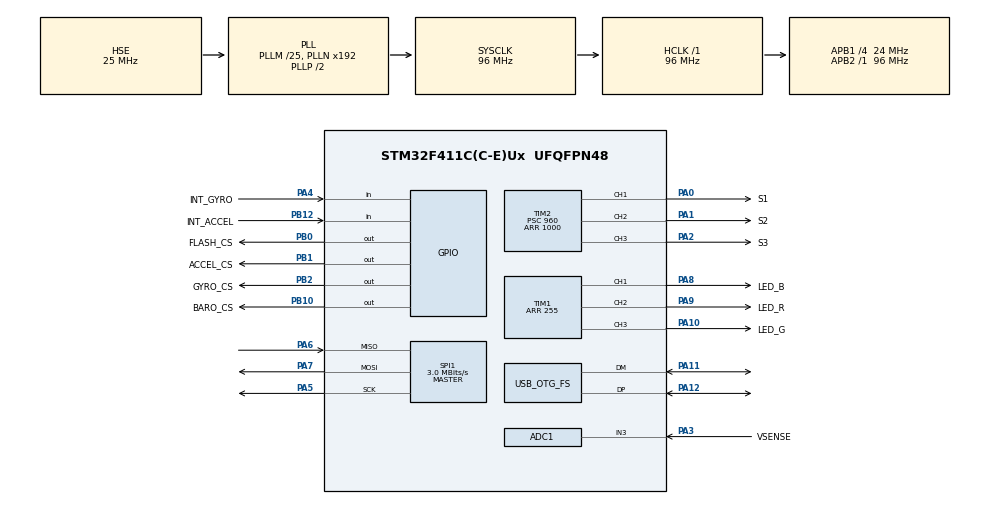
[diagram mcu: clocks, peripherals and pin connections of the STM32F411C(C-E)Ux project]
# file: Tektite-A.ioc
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ADC1.Channel-0\#ChannelRegularConversion=ADC_CHANNEL_3
ADC1.NbrOfConversionFlag=1
ADC1.Rank-0\#ChannelRegularConversion=1
ADC1.SamplingTime-0\#ChannelRegularConversion=ADC_SAMPLETIME_3CYCLES
ADC1.master=1
Mcu.Family=STM32F4
Mcu.Name=STM32F411C(C-E)Ux
Mcu.Package=UFQFPN48
NVIC.OTG_FS_IRQn=true\:0\:0\:false\:false\:true\:false\:true\:true
NVIC.PriorityGroup=NVIC_PRIORITYGROUP_4
NimaLTD.I-CUBE-SPIF.2.3.1.DriverJjSPIF=true
NimaLTD.I-CUBE-SPIF.2.3.1.SPIF_DEBUG=SPIF_DEBUG_DISABLE
PA0-WKUP.GPIO_Label=S1
PA0-WKUP.GPIO_PuPd=GPIO_PULLDOWN
PA0-WKUP.Signal=S_TIM2_CH1_ETR
PA1.GPIO_Label=S2
PA1.GPIO_PuPd=GPIO_PULLDOWN
PA1.Signal=S_TIM2_CH2
PA10.GPIO_Label=LED_G
PA10.Signal=S_TIM1_CH3
PA11.Mode=Device_Only
PA11.Signal=USB_OTG_FS_DM
PA12.Mode=Device_Only
PA12.Signal=USB_OTG_FS_DP
PA13.Mode=Serial_Wire
PA13.Signal=SYS_JTMS-SWDIO
PA14.Mode=Serial_Wire
PA14.Signal=SYS_JTCK-SWCLK
PA2.GPIO_Label=S3
PA2.GPIO_PuPd=GPIO_PULLDOWN
PA2.Signal=S_TIM2_CH3
PA3.GPIO_Label=VSENSE
PA3.Signal=ADCx_IN3
PA4.GPIO_Label=INT_GYRO
PA4.Signal=GPIO_Input
PA5.Mode=Full_Duplex_Master
PA5.Signal=SPI1_SCK
PA6.Mode=Full_Duplex_Master
PA6.Signal=SPI1_MISO
PA7.Mode=Full_Duplex_Master
PA7.Signal=SPI1_MOSI
PA8.GPIO_Label=LED_B
PA8.Signal=S_TIM1_CH1
PA9.GPIO_Label=LED_R
PA9.Signal=S_TIM1_CH2
PB0.GPIO_Label=FLASH_CS
PB0.GPIO_Speed=GPIO_SPEED_FREQ_VERY_HIGH
PB0.PinState=GPIO_PIN_SET
PB0.Signal=GPIO_Output
PB1.GPIO_Label=ACCEL_CS
PB1.GPIO_Speed=GPIO_SPEED_FREQ_VERY_HIGH
PB1.PinState=GPIO_PIN_SET
PB1.Signal=GPIO_Output
PB10.GPIO_Label=BARO_CS
PB10.GPIO_Speed=GPIO_SPEED_FREQ_VERY_HIGH
PB10.PinState=GPIO_PIN_SET
PB10.Signal=GPIO_Output
PB12.GPIO_Label=INT_ACCEL
PB12.Signal=GPIO_Input
PB2.GPIO_Label=GYRO_CS
PB2.GPIO_Speed=GPIO_SPEED_FREQ_VERY_HIGH
PB2.PinState=GPIO_PIN_SET
PB2.Signal=GPIO_Output
PH0\ -\ OSC_IN.Mode=HSE-External-Oscillator
PH0\ -\ OSC_IN.Signal=RCC_OSC_IN
PH1\ -\ OSC_OUT.Mode=HSE-External-Oscillator
PH1\ -\ OSC_OUT.Signal=RCC_OSC_OUT
ProjectManager.HeapSize=0x200
ProjectManager.StackSize=0x400
ProjectManager.TargetToolchain=STM32CubeIDE
RCC.48MHZClocksFreq_Value=48000000
RCC.AHBFreq_Value=96000000
RCC.APB1CLKDivider=RCC_HCLK_DIV4
RCC.APB1Freq_Value=24000000
RCC.APB1TimFreq_Value=48000000
RCC.APB2Freq_Value=96000000
RCC.APB2TimFreq_Value=96000000
RCC.CortexFreq_Value=96000000
RCC.HCLKFreq_Value=96000000
RCC.HSE_VALUE=25000000
RCC.HSI_VALUE=16000000
RCC.LSE_VALUE=32768
RCC.PLLM=25
RCC.SYSCLKFreq_VALUE=96000000
RCC.SYSCLKSource=RCC_SYSCLKSOURCE_PLLCLK
RCC.VCOOutputFreq_Value=192000000
SH.ADCx_IN3.0=ADC1_IN3,IN3
SH.S_TIM1_CH1.0=TIM1_CH1,PWM Generation1 CH1
SH.S_TIM1_CH2.0=TIM1_CH2,PWM Generation2 CH2
SH.S_TIM1_CH3.0=TIM1_CH3,PWM Generation3 CH3
SH.S_TIM2_CH1_ETR.0=TIM2_CH1,PWM Generation1 CH1
SH.S_TIM2_CH2.0=TIM2_CH2,PWM Generation2 CH2
SH.S_TIM2_CH3.0=TIM2_CH3,PWM Generation3 CH3
SPI1.BaudRatePrescaler=SPI_BAUDRATEPRESCALER_32
SPI1.CalculateBaudRate=3.0 MBits/s
SPI1.DataSize=SPI_DATASIZE_8BIT
SPI1.Direction=SPI_DIRECTION_2LINES
SPI1.Mode=SPI_MODE_MASTER
SPI1.VirtualType=VM_MASTER
TIM1.AutoReloadPreload=TIM_AUTORELOAD_PRELOAD_ENABLE
TIM1.Channel-PWM\ Generation1\ CH1=TIM_CHANNEL_1
TIM1.Channel-PWM\ Generation2\ CH2=TIM_CHANNEL_2
TIM1.Channel-PWM\ Generation3\ CH3=TIM_CHANNEL_3
TIM1.Period=255
TIM2.Channel-PWM\ Generation1\ CH1=TIM_CHANNEL_1
TIM2.Channel-PWM\ Generation2\ CH2=TIM_CHANNEL_2
TIM2.Channel-PWM\ Generation3\ CH3=TIM_CHANNEL_3
TIM2.Period=1000
TIM2.Prescaler=960
USB_DEVICE.CLASS_NAME_FS=CDC
USB_DEVICE.VirtualMode=Cdc
USB_DEVICE.VirtualModeFS=Cdc_FS
USB_OTG_FS.VirtualMode=Device_Only
VP_NimaLTD.I-CUBE-SPIF_VS_DriverJjSPIF_1.0.0_2.3.1.Mode=DriverJjSPIF
VP_TIM1_VS_ClockSourceINT.Mode=Internal
VP_TIM2_VS_ClockSourceINT.Mode=Internal
VP_USB_DEVICE_VS_USB_DEVICE_CDC_FS.Mode=CDC_FS
board=custom

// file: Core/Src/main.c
/* USER CODE BEGIN Header */
/**
  ******************************************************************************
  * @file           : main.c
  * @brief          : Main program body
  ******************************************************************************
  * @attention
  *
  * Copyright (c) 2024 STMicroelectronics.
  * All rights reserved.
  *
  * This software is licensed under terms that can be found in the LICENSE file
  * in the root directory of this software component.
  * If no LICENSE file comes with this software, it is provided AS-IS.
  *
  ******************************************************************************
  */
/* USER CODE END Header */
#include "main.h"
#include "adc.h"
#include "spi.h"
#include "tim.h"
#include "usb_device.h"
#include "gpio.h"

/* USER CODE BEGIN Includes */
#include <string.h>
#include <math.h>
#include "sensor.h"
#include "states.h"
/* USER CODE END Includes */

void SystemClock_Config(void);
/* USER CODE BEGIN PFP */
extern uint8_t CDC_Transmit_FS(uint8_t* Buf, uint16_t Len);
/* USER CODE END PFP */

int main(void)
{

  /* MCU Configuration--------------------------------------------------------*/

  /* Reset of all peripherals, Initializes the Flash interface and the Systick. */
  HAL_Init();

  /* Configure the system clock */
  SystemClock_Config();

  /* Initialize all configured peripherals */
  MX_GPIO_Init();
  MX_SPI1_Init();
  MX_USB_DEVICE_Init();
  MX_TIM2_Init();
  MX_TIM1_Init();
  MX_ADC1_Init();
  /* USER CODE BEGIN 2 */
  SensorInit();
  //CalcStdev();

  // Filter testing code
  SensorRawUpdate();
  SensorFilterReset();

  //float sigmaTot = 0;

  /*float total = 0;
  float values[1000];
  for (int i = 0; i < 1000; i++) {
	  LEDWrite(i/6, i/6, i/6);
	  SensorRawUpdate();
	  total += state.altr;
	  values[i] = state.altr;
	  HAL_Delay(12);
  }
  for (int i = 0; i < 1000; i++) {
	  sigmaTot += powf(((total/1000.0f)-values[i]), 2.0f);
  }
  sigmaTot = sqrtf(sigmaTot/999.0f);*/

  /*int sc = 0;
  while (1) {
	  SensorRawUpdate();
	  SensorFilterUpdate();
	  sc++;
	  if (sc % 50 == 0) {
		 printf("alt:%f,vz:%f,az:%f,altr:%f,vD:%f,sigma:%f\n", state.alt, state.vz, state.az, state.altr, delayedVel, sigmaTot);
	  }
  }*/

  /* USER CODE END 2 */

  /* Infinite loop */
  while (1)
  {

    /* USER CODE BEGIN 3 */
	 SensorRawUpdate();
	 StateUpdate();
  }
  /* USER CODE END 3 */
}

void SystemClock_Config(void)
{
  RCC_OscInitTypeDef RCC_OscInitStruct = {0};
  RCC_ClkInitTypeDef RCC_ClkInitStruct = {0};

  /** Configure the main internal regulator output voltage
  */
  __HAL_RCC_PWR_CLK_ENABLE();
  __HAL_PWR_VOLTAGESCALING_CONFIG(PWR_REGULATOR_VOLTAGE_SCALE1);

  /** Initializes the RCC Oscillators according to the specified parameters
  * in the RCC_OscInitTypeDef structure.
  */
  RCC_OscInitStruct.OscillatorType = RCC_OSCILLATORTYPE_HSE;
  RCC_OscInitStruct.HSEState = RCC_HSE_ON;
  RCC_OscInitStruct.PLL.PLLState = RCC_PLL_ON;
  RCC_OscInitStruct.PLL.PLLSource = RCC_PLLSOURCE_HSE;
  RCC_OscInitStruct.PLL.PLLM = 25;
  RCC_OscInitStruct.PLL.PLLN = 192;
  RCC_OscInitStruct.PLL.PLLP = RCC_PLLP_DIV2;
  RCC_OscInitStruct.PLL.PLLQ = 4;
  if (HAL_RCC_OscConfig(&RCC_OscInitStruct) != HAL_OK)
  {
    Error_Handler();
  }

  /** Initializes the CPU, AHB and APB buses clocks
  */
  RCC_ClkInitStruct.ClockType = RCC_CLOCKTYPE_HCLK|RCC_CLOCKTYPE_SYSCLK
                              |RCC_CLOCKTYPE_PCLK1|RCC_CLOCKTYPE_PCLK2;
  RCC_ClkInitStruct.SYSCLKSource = RCC_SYSCLKSOURCE_PLLCLK;
  RCC_ClkInitStruct.AHBCLKDivider = RCC_SYSCLK_DIV1;
  RCC_ClkInitStruct.APB1CLKDivider = RCC_HCLK_DIV4;
  RCC_ClkInitStruct.APB2CLKDivider = RCC_HCLK_DIV1;

  if (HAL_RCC_ClockConfig(&RCC_ClkInitStruct, FLASH_LATENCY_3) != HAL_OK)
  {
    Error_Handler();
  }
}

/* USER CODE BEGIN 4 */
/**
  * @brief  Retargets the C library printf function to the USART.
  * @PAram  None
  * @retval None
  */
int _write(int file, char *ptr, int len) {
    CDC_Transmit_FS((uint8_t*) ptr, len); return len;
}
/* USER CODE END 4 */

void Error_Handler(void)
{
  __disable_irq();
  while (1)
  {
  }
}
